// =============================================================
// can0.dbc — CAN0 通道 DBC 模板（动力 / 电池类）
// 启用方式：在 config.txt 中写入 `can_dbc can0 config/can0.dbc`，
//           或在 Web 配置页上传本文件。
// =============================================================
//
// 解析器（source/can/dbc_parser.c）只识别以下两类行，其余行均忽略：
//
// 1) 报文行：BO_ <ID> <报文名>: <DLC> <发送节点>
//    BO_ 256 EngineData: 8 Gateway
//    - ID：十进制 CAN ID
//    - 标准帧：0 ~ 0x7FF（2047）
//    - 扩展帧：0x80000000 | (29 位 ID)，即最高位 bit31 置 1 表示扩展帧
//    - DLC：数据长度（字节），经典 CAN 0 ~ 8
//
// 2) 信号行：SG_ <信号名> : <起始位>|<长度>@<字节序><符号> (<因子>,<偏移>) [<最小>|<最大>] "<单位>" <接收节点>
//    SG_ EngineSpeed : 0|16@1+ (0.25,0) [0|16383.75] "rpm" Gateway
//    - 起始位：信号在报文中的最低位偏移（从 0 起）
//    - 长度：信号位宽
//    - 字节序：1 = Intel(小端/LSB first)，0 = Motorola(大端/MSB first)
//    - 符号：+ 无符号，- 有符号（补码）
//    - 因子/偏移：物理值 = 原始值 * 因子 + 偏移
//
// 注：`//` 为注释行，解析时自动跳过。
// =============================================================

VERSION "1.0"

BU_: Engine Battery Gateway

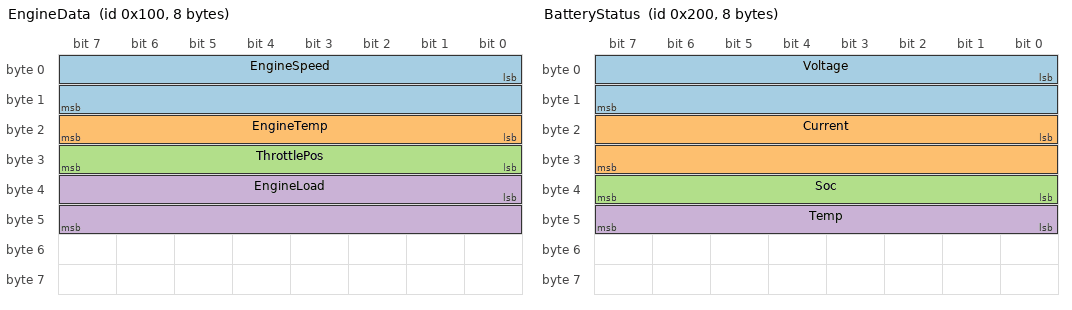
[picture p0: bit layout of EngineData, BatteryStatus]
BO_ 256 EngineData: 8 Gateway
 SG_ EngineSpeed : 0|16@1+ (0.25,0) [0|16383.75] "rpm" Gateway
 SG_ EngineTemp : 16|8@1+ (1,-40) [-40|215] "degC" Gateway
 SG_ ThrottlePos : 24|8@1+ (0.4,0) [0|100] "%" Gateway
 SG_ EngineLoad : 32|16@1+ (0.001,0) [0|65.535] "%" Gateway

BO_ 512 BatteryStatus: 8 Gateway
 SG_ Voltage : 0|16@1+ (0.001,0) [0|65.535] "V" Gateway
 SG_ Current : 16|16@1- (0.1,0) [-3276.8|3276.7] "A" Gateway
 SG_ Soc : 32|8@1+ (0.5,0) [0|100] "%" Gateway
 SG_ Temp : 40|8@1+ (1,-40) [-40|215] "degC" Gateway
